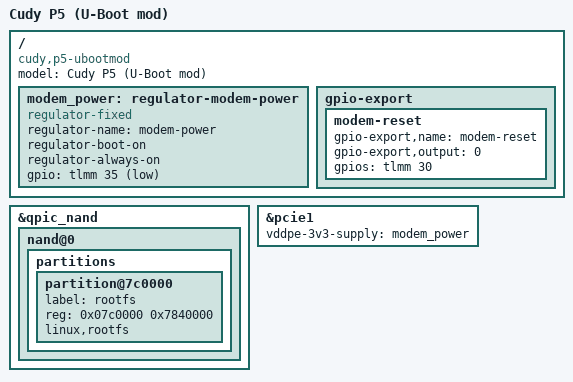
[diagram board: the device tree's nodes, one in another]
// SPDX-License-Identifier: GPL-2.0-or-later OR MIT

/dts-v1/;

#include "ipq5018-cudy-p5.dtsi"

/ {
	model = "Cudy P5 (U-Boot mod)";
	compatible = "cudy,p5-ubootmod", "cudy,p5", "qcom,ipq5018";

	/* Custom U-Boot leaves modem power off for Linux. */
	modem_power: regulator-modem-power {
		compatible = "regulator-fixed";
		regulator-name = "modem-power";
		regulator-boot-on;
		regulator-always-on;
		gpio = <&tlmm 35 GPIO_ACTIVE_LOW>;
	};

	gpio-export {
		modem-reset {
			gpio-export,name = "modem-reset";
			gpio-export,output = <0>;
			gpios = <&tlmm 30 GPIO_ACTIVE_HIGH>;
		};
	};
};

&qpic_nand {
	nand@0 {
		partitions {
			partition@7c0000 {
				label = "rootfs";
				reg = <0x07c0000 0x7840000>;
				linux,rootfs;
			};
		};
	};
};

&pcie1 {
	vddpe-3v3-supply = <&modem_power>;
};
